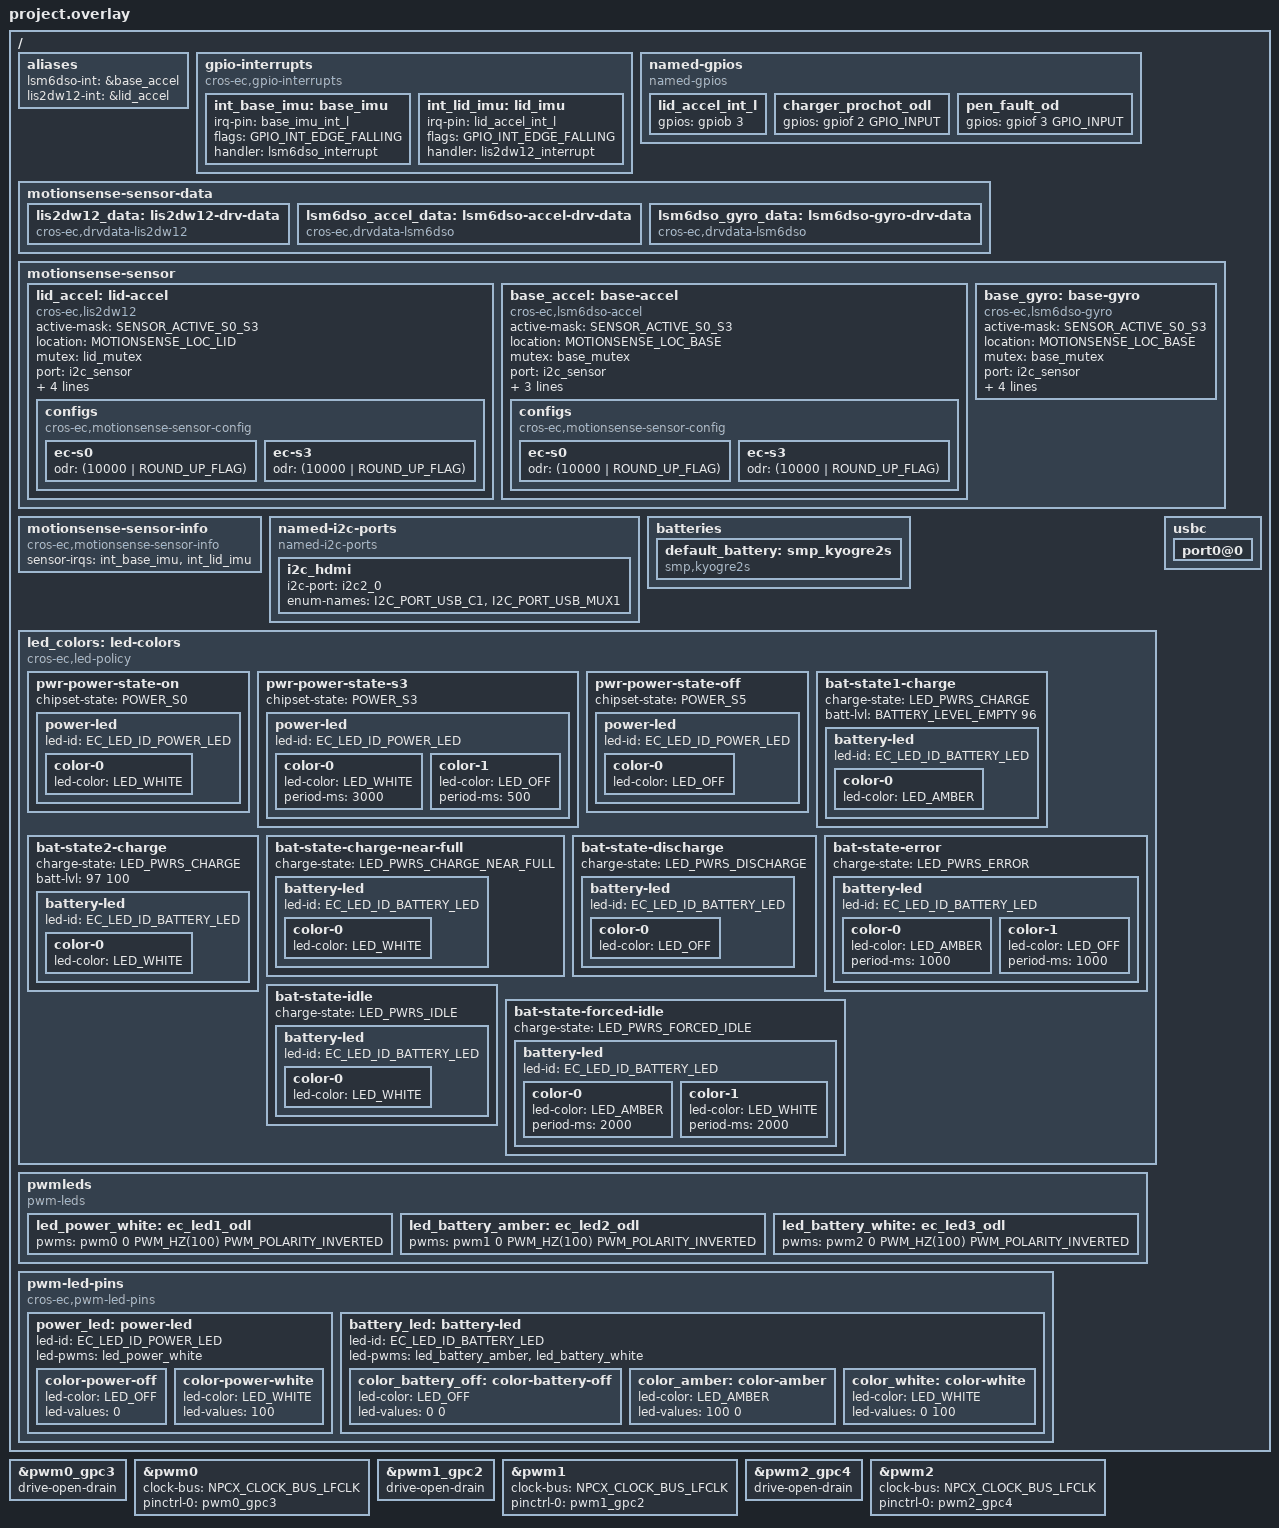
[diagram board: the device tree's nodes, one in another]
/* Copyright 2024 The ChromiumOS Authors
 * Use of this source code is governed by a BSD-style license that can be
 * found in the LICENSE file.
 */

/* Corsola program common DTS includes */

#include "../common.dtsi"
#include "../power_signal.dtsi"
#include "../usba.dtsi"
#include "../npcx_adc.dtsi"
#include "../npcx_host_interface.dtsi"
#include "../npcx_i2c.dtsi"
#include "../npcx_interrupts.dtsi"
#include "../npcx_gpio.dtsi"
#include "../npcx_keyboard.dtsi"
#include "../npcx_motionsense.dtsi"
#include "../npcx_usbc.dtsi"
#include "../npcx_default_gpio_pinctrl.dtsi"
#include <dt-bindings/battery.h>

/* board override */
/ {
	aliases {
		/*
		 * motion sense's <>_INT_EVENT is handled
		 * by alias. Using the alias, each driver creates
		 * its own <>_INT_EVENT.
		 */
		lsm6dso-int = &base_accel;
		lis2dw12-int = &lid_accel;
	};

	gpio-interrupts {
		compatible = "cros-ec,gpio-interrupts";
		/delete-node/ int_base_imu;

		int_base_imu: base_imu {
			irq-pin = <&base_imu_int_l>;
			flags = <GPIO_INT_EDGE_FALLING>;
			handler = "lsm6dso_interrupt";
		};

		int_lid_imu: lid_imu {
			irq-pin = <&lid_accel_int_l>;
			flags = <GPIO_INT_EDGE_FALLING>;
			handler = "lis2dw12_interrupt";
		};
	};

	named-gpios {
		compatible = "named-gpios";
		/delete-node/ ec_entering_rw;
		/delete-node/ lid_accel_int_l;
		/delete-node/ charger_prochot_odl;

		lid_accel_int_l: lid_accel_int_l {
			gpios = <&gpiob 3 (GPIO_INPUT | GPIO_VOLTAGE_1P8)>;
		};
		charger_prochot_odl {
			gpios = <&gpiof 2 GPIO_INPUT>;
		};
		pen_fault_od {
			gpios = <&gpiof 3 GPIO_INPUT>;
		};
	};

	/*
	 * Driver specific data. A driver-specific data can be shared with
	 * different motion sensors while they are using the same driver.
	 *
	 * If a node's compatible starts with "cros-ec,accelgyro-", it is for
	 * a common structure defined in accelgyro.h.
	 * e.g) compatible = "cros-ec,accelgyro-als-drv-data" is for
	 * "struct als_drv_data_t" in accelgyro.h
	 */
	motionsense-sensor-data {
		lis2dw12_data: lis2dw12-drv-data {
			compatible = "cros-ec,drvdata-lis2dw12";
			status = "okay";
		};

		lsm6dso_accel_data: lsm6dso-accel-drv-data {
			compatible = "cros-ec,drvdata-lsm6dso";
			status = "okay";
		};

		lsm6dso_gyro_data: lsm6dso-gyro-drv-data {
			compatible = "cros-ec,drvdata-lsm6dso";
			status = "okay";
		};
	};

	motionsense-sensor {
		lid_accel: lid-accel {
			compatible = "cros-ec,lis2dw12";
			status = "okay";

			active-mask = "SENSOR_ACTIVE_S0_S3";
			location = "MOTIONSENSE_LOC_LID";
			mutex = <&lid_mutex>;
			port = <&i2c_sensor>;
			rot-standard-ref = <&lid_rot_ref>;
			default-range = <2>;
			drv-data = <&lis2dw12_data>;
			i2c-spi-addr-flags = "LIS2DWL_ADDR1_FLAGS";
			configs {
				compatible =
					"cros-ec,motionsense-sensor-config";
				ec-s0 {
					odr = <(10000 | ROUND_UP_FLAG)>;
				};
				ec-s3 {
					odr = <(10000 | ROUND_UP_FLAG)>;
				};
			};
		};

		base_accel: base-accel {
			compatible = "cros-ec,lsm6dso-accel";
			status = "okay";

			active-mask = "SENSOR_ACTIVE_S0_S3";
			location = "MOTIONSENSE_LOC_BASE";
			mutex = <&base_mutex>;
			port = <&i2c_sensor>;
			rot-standard-ref = <&base_rot_ref>;
			drv-data = <&lsm6dso_accel_data>;
			i2c-spi-addr-flags = "LSM6DSO_ADDR1_FLAGS";
			configs {
				compatible =
					"cros-ec,motionsense-sensor-config";
				ec-s0 {
					odr = <(10000 | ROUND_UP_FLAG)>;
				};
				ec-s3 {
					odr = <(10000 | ROUND_UP_FLAG)>;
				};
			};
		};

		base_gyro: base-gyro {
			compatible = "cros-ec,lsm6dso-gyro";
			status = "okay";

			active-mask = "SENSOR_ACTIVE_S0_S3";
			location = "MOTIONSENSE_LOC_BASE";
			mutex = <&base_mutex>;
			port = <&i2c_sensor>;
			rot-standard-ref = <&base_rot_ref>;
			default-range = <(1000 | ROUND_UP_FLAG)>; /* dps */
			drv-data = <&lsm6dso_gyro_data>;
			i2c-spi-addr-flags = "LSM6DSO_ADDR1_FLAGS";
		};
	};

	motionsense-sensor-info {
		compatible = "cros-ec,motionsense-sensor-info";

		/*
		 * list of GPIO interrupts that have to
		 * be enabled at initial stage
		 */
		sensor-irqs = <&int_base_imu &int_lid_imu>;
	};

	named-i2c-ports {
		compatible = "named-i2c-ports";

		/delete-node/ usb-c1;

		i2c_hdmi: i2c_hdmi {
			i2c-port = <&i2c2_0>;
			enum-names = "I2C_PORT_USB_C1",
				"I2C_PORT_USB_MUX1";
		};
	};

	batteries {
		default_battery: smp_kyogre2s {
			compatible = "smp,kyogre2s", "battery-smart";
		};
	};

	led_colors: led-colors {
		compatible = "cros-ec,led-policy";

		pwr-power-state-on {
			chipset-state = "POWER_S0";

			power-led {
				led-id = "EC_LED_ID_POWER_LED";

				color-0 {
					led-color = "LED_WHITE";
				};
			};
		};

		pwr-power-state-s3 {
			chipset-state = "POWER_S3";

			power-led {
				led-id = "EC_LED_ID_POWER_LED";

				color-0 {
					led-color = "LED_WHITE";
					period-ms = <3000>;
				};

				color-1 {
					led-color = "LED_OFF";
					period-ms = <500>;
				};
			};
		};

		pwr-power-state-off {
			chipset-state = "POWER_S5";

			power-led {
				led-id = "EC_LED_ID_POWER_LED";
				color-0 {
					led-color = "LED_OFF";
				};
			};
		};

		bat-state1-charge {
			charge-state = "LED_PWRS_CHARGE";
			/* Battery display percent range (>= 0, <= 96%) */
			batt-lvl = <BATTERY_LEVEL_EMPTY 96>;

			battery-led {
				led-id = "EC_LED_ID_BATTERY_LED";
				color-0 {
					led-color = "LED_AMBER";
				};
			};
		};

		bat-state2-charge {
			charge-state = "LED_PWRS_CHARGE";
			/* Battery display percent range (>= 97, <= 100) */
			batt-lvl = <97 100>;

			battery-led {
				led-id = "EC_LED_ID_BATTERY_LED";
				color-0 {
					led-color = "LED_WHITE";
				};
			};
		};

		bat-state-charge-near-full {
			charge-state = "LED_PWRS_CHARGE_NEAR_FULL";

			battery-led {
				led-id = "EC_LED_ID_BATTERY_LED";
				color-0 {
					led-color = "LED_WHITE";
				};
			};
		};

		bat-state-discharge {
			charge-state = "LED_PWRS_DISCHARGE";

			battery-led {
				led-id = "EC_LED_ID_BATTERY_LED";
				color-0 {
					led-color = "LED_OFF";
				};
			};
		};

		bat-state-error {
			charge-state = "LED_PWRS_ERROR";

			battery-led {
				led-id = "EC_LED_ID_BATTERY_LED";
				color-0 {
					led-color = "LED_AMBER";
					period-ms = <1000>;
				};
				color-1 {
					led-color = "LED_OFF";
					period-ms = <1000>;
				};
			};
		};

		bat-state-idle {
			charge-state = "LED_PWRS_IDLE";

			battery-led {
				led-id = "EC_LED_ID_BATTERY_LED";
				color-0 {
					led-color = "LED_WHITE";
				};
			};
		};

		bat-state-forced-idle {
			charge-state = "LED_PWRS_FORCED_IDLE";

			battery-led {
				led-id = "EC_LED_ID_BATTERY_LED";
				color-0 {
					led-color = "LED_AMBER";
					period-ms = <2000>;
				};
				color-1 {
					led-color = "LED_WHITE";
					period-ms = <2000>;
				};
			};
		};
	};

	/*
	 * The hardware design sets:
	 * - PWM0 as the white light for Power LED
	 * - PWM1 as the amber light for Charge LED (charging with no near full)
	 * - PWM2 as the white light for Charge LED (charging with near full or no charging)
	 */
	pwmleds {
		compatible = "pwm-leds";
		led_power_white: ec_led1_odl {
			pwms = <&pwm0 0 PWM_HZ(100) PWM_POLARITY_INVERTED>;
		};
		led_battery_amber: ec_led2_odl {
			pwms = <&pwm1 0 PWM_HZ(100) PWM_POLARITY_INVERTED>;
		};
		led_battery_white: ec_led3_odl {
			pwms = <&pwm2 0 PWM_HZ(100) PWM_POLARITY_INVERTED>;
		};
	};

	pwm-led-pins {
		compatible = "cros-ec,pwm-led-pins";

		power_led: power-led {
			led-id = "EC_LED_ID_POWER_LED";
			led-pwms = <&led_power_white>;

			color-power-off {
				led-color = "LED_OFF";
				led-values = <0>;
			};

			color-power-white {
				led-color = "LED_WHITE";
				led-values = <100>;
			};
		};

		battery_led: battery-led {
			led-id = "EC_LED_ID_BATTERY_LED";
			led-pwms = <&led_battery_amber &led_battery_white>;

			color_battery_off: color-battery-off {
				led-color = "LED_OFF";
				led-values = <0 0>;
			};

			color_amber: color-amber {
				led-color = "LED_AMBER";
				led-values = <100 0>;
			};

			color_white: color-white {
				led-color = "LED_WHITE";
				led-values = <0 100>;
			};
		};
	};

	usbc {
		port0@0 {
			/delete-property/ bc12;
		};
	};
};

/* White LED */
&pwm0_gpc3 {
	drive-open-drain;
};

&pwm0 {
	status = "okay";
	clock-bus = "NPCX_CLOCK_BUS_LFCLK";
	pinctrl-0 = <&pwm0_gpc3>;
	pinctrl-names = "default";
};

/* Amber LED */
&pwm1_gpc2 {
	drive-open-drain;
};

&pwm1 {
	status = "okay";
	clock-bus = "NPCX_CLOCK_BUS_LFCLK";
	pinctrl-0 = <&pwm1_gpc2>;
	pinctrl-names = "default";
};

/* White LED */
&pwm2_gpc4 {
	drive-open-drain;
};

&pwm2 {
	status = "okay";
	clock-bus = "NPCX_CLOCK_BUS_LFCLK";
	pinctrl-0 = <&pwm2_gpc4>;
	pinctrl-names = "default";
};

/* Omit BC12 of USBC port0 */
/delete-node/ &int_usb_c0_bc12;
/delete-node/ &gpio_usb_c0_bc12_int_odl;
/delete-node/ &bc12_port0;
